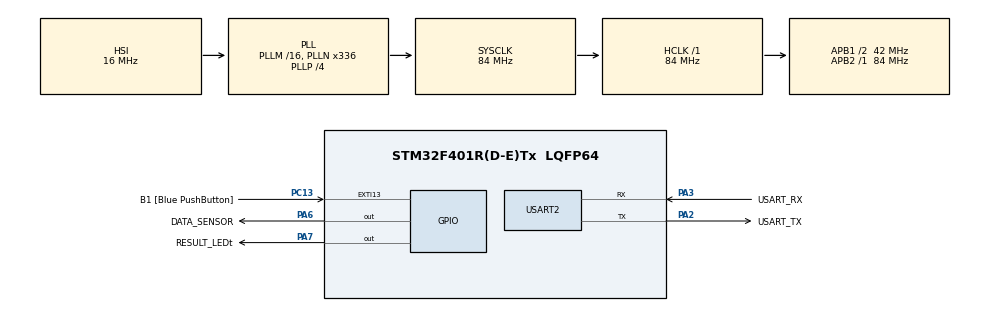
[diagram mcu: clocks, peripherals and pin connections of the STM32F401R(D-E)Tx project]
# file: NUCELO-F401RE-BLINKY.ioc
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Mcu.Family=STM32F4
Mcu.Name=STM32F401R(D-E)Tx
Mcu.Package=LQFP64
NVIC.PriorityGroup=NVIC_PRIORITYGROUP_0
PA13.GPIO_Label=TMS
PA13.Mode=Serial_Wire
PA13.Signal=SYS_JTMS-SWDIO
PA14.GPIO_Label=TCK
PA14.Mode=Serial_Wire
PA14.Signal=SYS_JTCK-SWCLK
PA2.GPIO_Label=USART_TX
PA2.GPIO_Mode=GPIO_MODE_AF_PP
PA2.GPIO_PuPd=GPIO_NOPULL
PA2.GPIO_Speed=GPIO_SPEED_FREQ_LOW
PA2.Mode=Asynchronous
PA2.Signal=USART2_TX
PA3.GPIO_Label=USART_RX
PA3.GPIO_Mode=GPIO_MODE_AF_PP
PA3.GPIO_PuPd=GPIO_NOPULL
PA3.GPIO_Speed=GPIO_SPEED_FREQ_LOW
PA3.Mode=Asynchronous
PA3.Signal=USART2_RX
PA6.GPIO_Label=DATA_SENSOR
PA6.Signal=GPIO_Output
PA7.GPIO_Label=RESULT_LED\t
PA7.Signal=GPIO_Output
PB3.GPIO_Label=SWO
PB3.Signal=SYS_JTDO-SWO
PC13-ANTI_TAMP.GPIO_Label=B1 [Blue PushButton]
PC13-ANTI_TAMP.GPIO_ModeDefaultEXTI=GPIO_MODE_IT_FALLING
PC13-ANTI_TAMP.GPIO_PuPd=GPIO_NOPULL
PC13-ANTI_TAMP.Signal=GPXTI13
PC14-OSC32_IN.Mode=LSE-External-Oscillator
PC14-OSC32_IN.Signal=RCC_OSC32_IN
PC15-OSC32_OUT.Mode=LSE-External-Oscillator
PC15-OSC32_OUT.Signal=RCC_OSC32_OUT
PH0\ -\ OSC_IN.Mode=HSE-External-Clock-Source
PH0\ -\ OSC_IN.Signal=RCC_OSC_IN
PH1\ -\ OSC_OUT.Mode=HSE-External-Clock-Source
PH1\ -\ OSC_OUT.Signal=RCC_OSC_OUT
ProjectManager.HeapSize=0x200
ProjectManager.StackSize=0x400
ProjectManager.TargetToolchain=STM32CubeIDE
RCC.48MHZClocksFreq_Value=48000000
RCC.AHBFreq_Value=84000000
RCC.APB1CLKDivider=RCC_HCLK_DIV2
RCC.APB1Freq_Value=42000000
RCC.APB1TimFreq_Value=84000000
RCC.APB2Freq_Value=84000000
RCC.APB2TimFreq_Value=84000000
RCC.CortexFreq_Value=84000000
RCC.HCLKFreq_Value=84000000
RCC.HSE_VALUE=8000000
RCC.HSI_VALUE=16000000
RCC.PLLN=336
RCC.PLLP=RCC_PLLP_DIV4
RCC.PLLQ=7
RCC.SYSCLKFreq_VALUE=84000000
RCC.SYSCLKSource=RCC_SYSCLKSOURCE_PLLCLK
RCC.VCOOutputFreq_Value=336000000
TIM1.Period=65535-1
TIM1.Prescaler=84-1
USART2.VirtualMode=VM_ASYNC
VP_TIM1_VS_ClockSourceINT.Mode=Internal
board=NUCLEO-F401RE

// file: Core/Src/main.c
/* USER CODE BEGIN Header */
/**
  ******************************************************************************
  * @file           : main.c
  * @brief          : Main program body
  ******************************************************************************
  * @attention
  *
  * Copyright (c) 2022 STMicroelectronics.
  * All rights reserved.
  *
  * This software is licensed under terms that can be found in the LICENSE file
  * in the root directory of this software component.
  * If no LICENSE file comes with this software, it is provided AS-IS.
  *
  ******************************************************************************
  */
#include "ds18b20.h"
#include "ds18b20_definitions.h"
#include "codes.h"
#include "delay.h"
/* USER CODE END Header */
#include "main.h"

/* USER CODE BEGIN PM */
#define DS18B20_PORT			DATA_SENSOR_GPIO_Port
#define DS18B20_PIN				DATA_SENSOR_Pin
////CODE RESULTS
//#define SUCCESS					0
//#define INITIALIZATION_FAIL		-1
////TIMES CHECK DATASHEET DS18B20
//#define M_RESET_PULSE_MINIMUN	480
//#define S_PRESENCE_PULSE		60  // Value between 60-240 uS
//#define M_RX_MINIMUN			480

/* USER CODE END PM */

TIM_HandleTypeDef htim1;

UART_HandleTypeDef huart2;

void SystemClock_Config(void);
static void MX_GPIO_Init(void);
static void MX_USART2_UART_Init(void);
static void MX_TIM1_Init(void);
/* USER CODE BEGIN PFP */
//void delay_us (uint16_t us);
//int8_t DS18B20_Initialization(uint8_t _DS18B20_PORT, uint8_t _DS18B20_PIN);
//void GPIO_Set_Pin_Output (GPIO_TypeDef *GPIOx, uint16_t GPIO_Pin);
//void GPIO_Set_Pin_Input (GPIO_TypeDef *GPIOx, uint16_t GPIO_Pin);
/* USER CODE END PFP */

/* USER CODE BEGIN 0 */

//void GPIO_Set_Pin_Output (GPIO_TypeDef *GPIOx, uint16_t GPIO_Pin)
//{
//	GPIO_InitTypeDef GPIO_InitStruct = {0};
//	GPIO_InitStruct.Pin = GPIO_Pin;
//	GPIO_InitStruct.Mode = GPIO_MODE_OUTPUT_PP;
//	GPIO_InitStruct.Speed = GPIO_SPEED_FREQ_LOW;
//	HAL_GPIO_Init(GPIOx, &GPIO_InitStruct);
//}
//
//void GPIO_Set_Pin_Input (GPIO_TypeDef *GPIOx, uint16_t GPIO_Pin)
//{
//	GPIO_InitTypeDef GPIO_InitStruct = {0};
//	GPIO_InitStruct.Pin = GPIO_Pin;
//	GPIO_InitStruct.Mode = GPIO_MODE_INPUT;
//	GPIO_InitStruct.Pull = GPIO_PULLUP;
//	HAL_GPIO_Init(GPIOx, &GPIO_InitStruct);
//}

//void delay_us (uint16_t us)
//{
//	__HAL_TIM_SET_COUNTER(&htim1,0);  // set the counter value a 0
//	while (__HAL_TIM_GET_COUNTER(&htim1) < us);  // wait for the counter to reach the us input in the parameter
//}

//int8_t DS18B20_Initialization(uint8_t _DS18B20_PORT, uint8_t _DS18B20_PIN)
//{
//	int8_t Response = 0;
//
//	GPIO_Set_Pin_Output(_DS18B20_PORT, _DS18B20_PIN);   // Set the pin as output
//	HAL_GPIO_WritePin (_DS18B20_PORT, _DS18B20_PIN, 0);  //BUS MASTER PULLING LOW
//	delay_us(M_RESET_PULSE_MINIMUN);   //Delay according to datasheet
//
//	GPIO_Set_Pin_Input(_DS18B20_PORT, _DS18B20_PIN); // Set the pin as input
//	delay_us(S_PRESENCE_PULSE);    //Delay according to datasheet
//
//	if (!(HAL_GPIO_ReadPin (_DS18B20_PORT, _DS18B20_PIN))) Response = SUCCESS;    //Check if the pin is low in that case the presence pulse is detected
//	else Response = INITIALIZATION_FAIL;
//
//	delay_us (M_RX_MINIMUN-S_PRESENCE_PULSE);
//
//	return Response;
//}

/* USER CODE END 0 */

int main(void)
{
  /* USER CODE BEGIN 1 */
	int8_t result=INITIALIZATION_FAIL;
	int16_t temp_reg_byte1=0, temp_reg_byte2=0;
	int16_t temp_reg=0;
	int16_t temp_value=0;
	float temperature_converted=0;
//	result++;
  /* USER CODE END 1 */

  /* MCU Configuration--------------------------------------------------------*/

  /* Reset of all peripherals, Initializes the Flash interface and the Systick. */
  HAL_Init();

  /* Configure the system clock */
  SystemClock_Config();

  /* Initialize all configured peripherals */
  MX_GPIO_Init();
  MX_USART2_UART_Init();
  MX_TIM1_Init();
  /* USER CODE BEGIN 2 */
  HAL_TIM_Base_Start(&htim1);
  delay_init(&htim1);
  /* USER CODE END 2 */

  /* Infinite loop */
  /* USER CODE BEGIN WHILE */
//  HAL_GPIO_WritePin (DS18B20_PORT, DS18B20_PIN, 0);
  while (1)
  {
    /* USER CODE END WHILE */

    /* USER CODE BEGIN 3 */

	  result=DS18B20_Initialization(DS18B20_PORT, DS18B20_PIN);
	  if(result==SUCCESS)
	  {
		  DS18B20_write_byte(ROM_CMD_SKIP_ROM);
		  DS18B20_write_byte(CMD_CONVERT_T);

		  HAL_Delay(800);
		  result=DS18B20_Initialization(DS18B20_PORT, DS18B20_PIN);
		  if(result==SUCCESS)
		  {
			  DS18B20_write_byte(ROM_CMD_SKIP_ROM);
			  DS18B20_write_byte(CMD_READ_SCRATCHPAD);

			  temp_reg_byte1= DS18B20_read_byte();
			  temp_reg_byte2= DS18B20_read_byte();
			  temp_reg= (temp_reg_byte2<<8)|temp_reg_byte1;
			  temp_value = (temp_reg & MASK_REG_TEM_INTEGER)>> MOVE_REG_TEM_INTEGER;
			  temperature_converted = (float)(temp_value/16);
		  }
	  }
//	  HAL_GPIO_TogglePin(GPIOA, GPIO_PIN_7);
//	  delay_us (100);
//	  HAL_Delay(50);
  }

  /* USER CODE END 3 */
}

void SystemClock_Config(void)
{
  RCC_OscInitTypeDef RCC_OscInitStruct = {0};
  RCC_ClkInitTypeDef RCC_ClkInitStruct = {0};

  /** Configure the main internal regulator output voltage
  */
  __HAL_RCC_PWR_CLK_ENABLE();
  __HAL_PWR_VOLTAGESCALING_CONFIG(PWR_REGULATOR_VOLTAGE_SCALE2);

  /** Initializes the RCC Oscillators according to the specified parameters
  * in the RCC_OscInitTypeDef structure.
  */
  RCC_OscInitStruct.OscillatorType = RCC_OSCILLATORTYPE_HSI;
  RCC_OscInitStruct.HSIState = RCC_HSI_ON;
  RCC_OscInitStruct.HSICalibrationValue = RCC_HSICALIBRATION_DEFAULT;
  RCC_OscInitStruct.PLL.PLLState = RCC_PLL_ON;
  RCC_OscInitStruct.PLL.PLLSource = RCC_PLLSOURCE_HSI;
  RCC_OscInitStruct.PLL.PLLM = 16;
  RCC_OscInitStruct.PLL.PLLN = 336;
  RCC_OscInitStruct.PLL.PLLP = RCC_PLLP_DIV4;
  RCC_OscInitStruct.PLL.PLLQ = 7;
  if (HAL_RCC_OscConfig(&RCC_OscInitStruct) != HAL_OK)
  {
    Error_Handler();
  }

  /** Initializes the CPU, AHB and APB buses clocks
  */
  RCC_ClkInitStruct.ClockType = RCC_CLOCKTYPE_HCLK|RCC_CLOCKTYPE_SYSCLK
                              |RCC_CLOCKTYPE_PCLK1|RCC_CLOCKTYPE_PCLK2;
  RCC_ClkInitStruct.SYSCLKSource = RCC_SYSCLKSOURCE_PLLCLK;
  RCC_ClkInitStruct.AHBCLKDivider = RCC_SYSCLK_DIV1;
  RCC_ClkInitStruct.APB1CLKDivider = RCC_HCLK_DIV2;
  RCC_ClkInitStruct.APB2CLKDivider = RCC_HCLK_DIV1;

  if (HAL_RCC_ClockConfig(&RCC_ClkInitStruct, FLASH_LATENCY_2) != HAL_OK)
  {
    Error_Handler();
  }
}

static void MX_TIM1_Init(void)
{

  TIM_ClockConfigTypeDef sClockSourceConfig = {0};
  TIM_MasterConfigTypeDef sMasterConfig = {0};

  htim1.Instance = TIM1;
  htim1.Init.Prescaler = 84-1;
  htim1.Init.CounterMode = TIM_COUNTERMODE_UP;
  htim1.Init.Period = 65535-1;
  htim1.Init.ClockDivision = TIM_CLOCKDIVISION_DIV1;
  htim1.Init.RepetitionCounter = 0;
  htim1.Init.AutoReloadPreload = TIM_AUTORELOAD_PRELOAD_DISABLE;
  if (HAL_TIM_Base_Init(&htim1) != HAL_OK)
  {
    Error_Handler();
  }
  sClockSourceConfig.ClockSource = TIM_CLOCKSOURCE_INTERNAL;
  if (HAL_TIM_ConfigClockSource(&htim1, &sClockSourceConfig) != HAL_OK)
  {
    Error_Handler();
  }
  sMasterConfig.MasterOutputTrigger = TIM_TRGO_RESET;
  sMasterConfig.MasterSlaveMode = TIM_MASTERSLAVEMODE_DISABLE;
  if (HAL_TIMEx_MasterConfigSynchronization(&htim1, &sMasterConfig) != HAL_OK)
  {
    Error_Handler();
  }

}

static void MX_USART2_UART_Init(void)
{

  huart2.Instance = USART2;
  huart2.Init.BaudRate = 115200;
  huart2.Init.WordLength = UART_WORDLENGTH_8B;
  huart2.Init.StopBits = UART_STOPBITS_1;
  huart2.Init.Parity = UART_PARITY_NONE;
  huart2.Init.Mode = UART_MODE_TX_RX;
  huart2.Init.HwFlowCtl = UART_HWCONTROL_NONE;
  huart2.Init.OverSampling = UART_OVERSAMPLING_16;
  if (HAL_UART_Init(&huart2) != HAL_OK)
  {
    Error_Handler();
  }

}

static void MX_GPIO_Init(void)
{
  GPIO_InitTypeDef GPIO_InitStruct = {0};

  /* GPIO Ports Clock Enable */
  __HAL_RCC_GPIOC_CLK_ENABLE();
  __HAL_RCC_GPIOH_CLK_ENABLE();
  __HAL_RCC_GPIOA_CLK_ENABLE();
  __HAL_RCC_GPIOB_CLK_ENABLE();

  /*Configure GPIO pin Output Level */
  HAL_GPIO_WritePin(GPIOA, DATA_SENSOR_Pin|RESULT_LED_Pin, GPIO_PIN_RESET);

  /*Configure GPIO pin : B1_Pin */
  GPIO_InitStruct.Pin = B1_Pin;
  GPIO_InitStruct.Mode = GPIO_MODE_IT_FALLING;
  GPIO_InitStruct.Pull = GPIO_NOPULL;
  HAL_GPIO_Init(B1_GPIO_Port, &GPIO_InitStruct);

  /*Configure GPIO pins : DATA_SENSOR_Pin RESULT_LED_Pin */
  GPIO_InitStruct.Pin = DATA_SENSOR_Pin|RESULT_LED_Pin;
  GPIO_InitStruct.Mode = GPIO_MODE_OUTPUT_PP;
  GPIO_InitStruct.Pull = GPIO_NOPULL;
  GPIO_InitStruct.Speed = GPIO_SPEED_FREQ_LOW;
  HAL_GPIO_Init(GPIOA, &GPIO_InitStruct);

}

void Error_Handler(void)
{
  __disable_irq();
  while (1)
  {
  }
}
